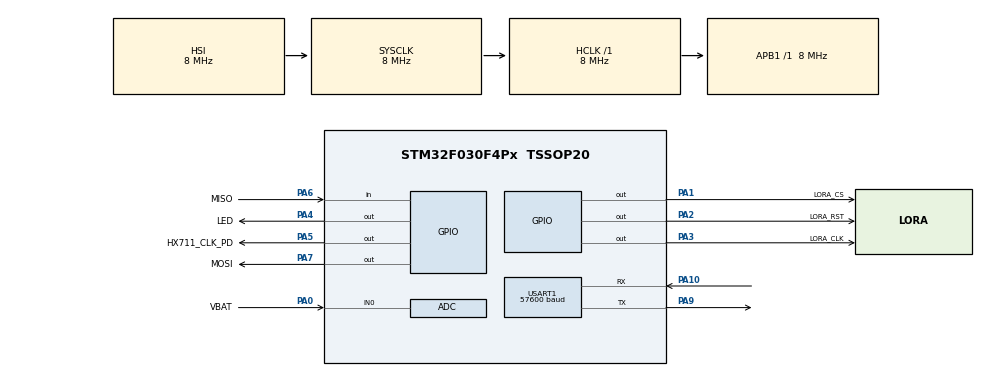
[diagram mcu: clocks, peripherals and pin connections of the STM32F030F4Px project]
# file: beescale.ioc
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ADC.ClockPrescaler=ADC_CLOCK_SYNC_PCLK_DIV2
ADC.ContinuousConvMode=DISABLE
ADC.EOCSelection=ADC_EOC_SEQ_CONV
ADC.LowPowerAutoPowerOff=DISABLE
ADC.LowPowerAutoWait=DISABLE
ADC.Overrun=ADC_OVR_DATA_PRESERVED
ADC.Resolution=ADC_RESOLUTION_8B
ADC.SamplingTime=ADC_SAMPLETIME_55CYCLES_5
Dma.ADC.0.Direction=DMA_PERIPH_TO_MEMORY
Dma.ADC.0.Instance=DMA1_Channel1
Dma.ADC.0.MemDataAlignment=DMA_MDATAALIGN_HALFWORD
Dma.ADC.0.MemInc=DMA_MINC_ENABLE
Dma.ADC.0.Mode=DMA_NORMAL
Dma.ADC.0.PeriphDataAlignment=DMA_PDATAALIGN_HALFWORD
Dma.ADC.0.PeriphInc=DMA_PINC_DISABLE
Dma.ADC.0.Priority=DMA_PRIORITY_LOW
Dma.Request0=ADC
Mcu.Family=STM32F0
Mcu.Name=STM32F030F4Px
Mcu.Package=TSSOP20
NVIC.DMA1_Channel1_IRQn=true\:0\:0\:false\:false\:true\:false\:true
PA0.GPIO_Label=VBAT
PA0.Mode=IN0
PA0.Signal=ADC_IN0
PA1.GPIO_Label=LORA_CS
PA1.PinState=GPIO_PIN_SET
PA1.Signal=GPIO_Output
PA10.Mode=Asynchronous
PA10.Signal=USART1_RX
PA2.GPIO_Label=LORA_RST
PA2.Signal=GPIO_Output
PA3.GPIO_Label=LORA_CLK
PA3.PinState=GPIO_PIN_RESET
PA3.Signal=GPIO_Output
PA4.GPIO_Label=LED
PA4.Signal=GPIO_Output
PA5.GPIO_Label=HX711_CLK_PD
PA5.PinState=GPIO_PIN_SET
PA5.Signal=GPIO_Output
PA6.GPIO_Label=MISO
PA6.Signal=GPIO_Input
PA7.GPIO_Label=MOSI
PA7.Signal=GPIO_Output
PA9.Mode=Asynchronous
PA9.Signal=USART1_TX
ProjectManager.HeapSize=0x0
ProjectManager.StackSize=0x400
ProjectManager.TargetToolchain=Makefile
RCC.AHBFreq_Value=8000000
RCC.APB1Freq_Value=8000000
RCC.APB1TimFreq_Value=8000000
RCC.HCLKFreq_Value=8000000
RCC.PLLMUL=RCC_PLL_MUL12
RCC.SYSCLKFreq_VALUE=8000000
USART1.BaudRate=57600
USART1.VirtualMode-Asynchronous=VM_ASYNC
VP_ADC_TempSens_Input.Mode=IN-TempSens
VP_ADC_Vref_Input.Mode=IN-Vrefint
board=custom

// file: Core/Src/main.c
/* USER CODE BEGIN Header */
/**
  ******************************************************************************
  * @file           : main.c
  * @brief          : Main program body
  ******************************************************************************
  * @attention
  *
  * <h2><center>&copy; Copyright (c) 2020 STMicroelectronics.
  * All rights reserved.</center></h2>
  *
  * This software component is licensed by ST under BSD 3-Clause license,
  * the "License"; You may not use this file except in compliance with the
  * License. You may obtain a copy of the License at:
  *                        opensource.org/licenses/BSD-3-Clause
  *
  ******************************************************************************
  */
/* USER CODE END Header */

#include "main.h"
#include "adc.h"
#include "dma.h"
#include "usart.h"
#include "gpio.h"

/* USER CODE BEGIN Includes */

void panic(void);
void app(void);

/* USER CODE END Includes */

void SystemClock_Config(void);

int main(void)
{

  /* MCU Configuration--------------------------------------------------------*/

  /* Reset of all peripherals, Initializes the Flash interface and the Systick. */
  HAL_Init();

  /* Configure the system clock */
  SystemClock_Config();

  /* Initialize all configured peripherals */
  MX_GPIO_Init();
  MX_DMA_Init();
  MX_ADC_Init();
  MX_USART1_UART_Init();
  /* USER CODE BEGIN 2 */

  app();
  /* USER CODE END 2 */

  /* Infinite loop */
  while (1)
  {

  }
}

void SystemClock_Config(void)
{
  RCC_OscInitTypeDef RCC_OscInitStruct = {0};
  RCC_ClkInitTypeDef RCC_ClkInitStruct = {0};
  RCC_PeriphCLKInitTypeDef PeriphClkInit = {0};

  /** Initializes the CPU, AHB and APB busses clocks
  */
  RCC_OscInitStruct.OscillatorType = RCC_OSCILLATORTYPE_HSI;
  RCC_OscInitStruct.HSIState = RCC_HSI_ON;
  RCC_OscInitStruct.HSICalibrationValue = RCC_HSICALIBRATION_DEFAULT;
  RCC_OscInitStruct.PLL.PLLState = RCC_PLL_NONE;
  if (HAL_RCC_OscConfig(&RCC_OscInitStruct) != HAL_OK)
  {
    Error_Handler();
  }
  /** Initializes the CPU, AHB and APB busses clocks
  */
  RCC_ClkInitStruct.ClockType = RCC_CLOCKTYPE_HCLK|RCC_CLOCKTYPE_SYSCLK
                              |RCC_CLOCKTYPE_PCLK1;
  RCC_ClkInitStruct.SYSCLKSource = RCC_SYSCLKSOURCE_HSI;
  RCC_ClkInitStruct.AHBCLKDivider = RCC_SYSCLK_DIV1;
  RCC_ClkInitStruct.APB1CLKDivider = RCC_HCLK_DIV1;

  if (HAL_RCC_ClockConfig(&RCC_ClkInitStruct, FLASH_LATENCY_0) != HAL_OK)
  {
    Error_Handler();
  }
  PeriphClkInit.PeriphClockSelection = RCC_PERIPHCLK_USART1;
  PeriphClkInit.Usart1ClockSelection = RCC_USART1CLKSOURCE_PCLK1;
  if (HAL_RCCEx_PeriphCLKConfig(&PeriphClkInit) != HAL_OK)
  {
    Error_Handler();
  }
}

void Error_Handler(void)
{
  /* USER CODE BEGIN Error_Handler_Debug */
  /* User can add his own implementation to report the HAL error return state */

  panic();

  /* USER CODE END Error_Handler_Debug */
}

#ifdef  USE_FULL_ASSERT
/**
  * @brief  Reports the name of the source file and the source line number
  *         where the assert_param error has occurred.
  * @param  file: pointer to the source file name
  * @param  line: assert_param error line source number
  * @retval None
  */
void assert_failed(char *file, uint32_t line)
{
  /* USER CODE BEGIN 6 */
    (void)file;
    (void)line;
    panic();
  /* USER CODE END 6 */
}
#endif /* USE_FULL_ASSERT */

/************************ (C) COPYRIGHT STMicroelectronics *****END OF FILE****/
